VERSION ""

BS_:

BU_:

// TX20 / CAN ID 0x11A / 282
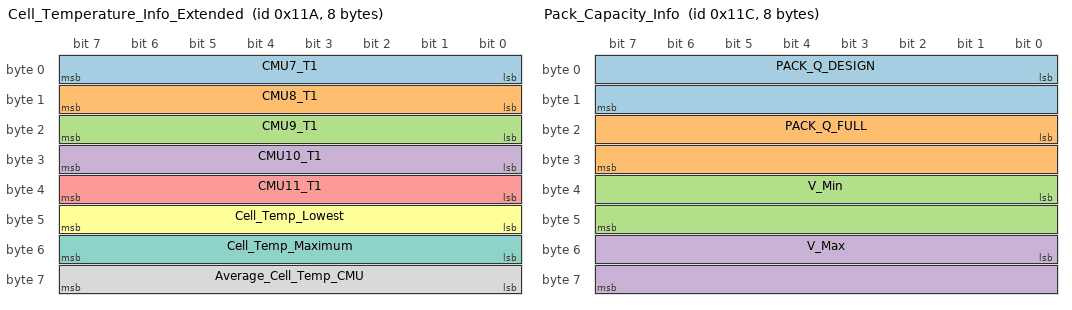
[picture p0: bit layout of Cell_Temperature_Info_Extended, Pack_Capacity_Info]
BO_ 282 Cell_Temperature_Info_Extended: 8 Vector__XXX
 SG_ CMU7_T1           : 0|8@1- (1,0) [-40|125] "C" Vector__XXX
 SG_ CMU8_T1           : 8|8@1- (1,0) [-40|125] "C" Vector__XXX
 SG_ CMU9_T1           : 16|8@1- (1,0) [-40|125] "C" Vector__XXX
 SG_ CMU10_T1          : 24|8@1- (1,0) [-40|125] "C" Vector__XXX
 SG_ CMU11_T1          : 32|8@1- (1,0) [-40|125] "C" Vector__XXX
 SG_ Cell_Temp_Lowest   : 40|8@1- (1,0) [-40|125] "C" Vector__XXX
 SG_ Cell_Temp_Maximum  : 48|8@1- (1,0) [-40|125] "C" Vector__XXX
 SG_ Average_Cell_Temp_CMU : 56|8@1- (1,0) [-40|125] "C" Vector__XXX

// TX14 / CAN ID 0x11C / 284
BO_ 284 Pack_Capacity_Info: 8 Vector__XXX
 SG_ PACK_Q_DESIGN : 0|16@1+ (0.1,0) [0|180] "Ah" Vector__XXX
 SG_ PACK_Q_FULL   : 16|16@1+ (0.1,0) [0|180] "Ah" Vector__XXX
 SG_ V_Min         : 32|16@1+ (0.1,0) [1|4] "mV" Vector__XXX
 SG_ V_Max         : 48|16@1+ (0.1,0) [1|4] "mV" Vector__XXX

// TX11 / CAN ID 0x12A / 298
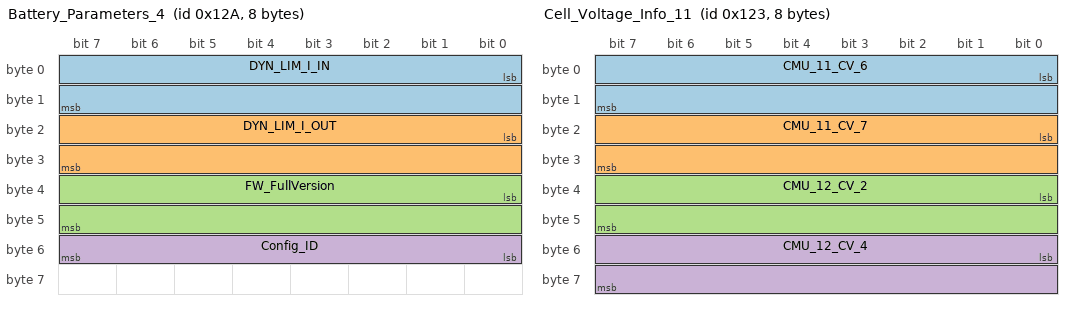
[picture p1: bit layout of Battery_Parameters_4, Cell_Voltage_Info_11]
BO_ 298 Battery_Parameters_4: 8 Vector__XXX
 SG_ DYN_LIM_I_IN : 0|16@1+ (0.1,0) [0|6553.5] "A" Vector__XXX
 SG_ DYN_LIM_I_OUT : 16|16@1+ (0.1,0) [0|6553.5] "A" Vector__XXX
 SG_ FW_FullVersion : 32|16@1+ (1,0) [0|65535] "" Vector__XXX
 SG_ Config_ID : 48|8@1+ (1,0) [0|255] "" Vector__XXX

// TX18 / CAN ID 0x123 / 291
BO_ 291 Cell_Voltage_Info_11: 8 Vector__XXX
 SG_ CMU_11_CV_6 : 0|16@1+ (0.1,0) [0|6553.5] "mV" Vector__XXX
 SG_ CMU_11_CV_7 : 16|16@1+ (0.1,0) [0|6553.5] "mV" Vector__XXX
 SG_ CMU_12_CV_2 : 32|16@1+ (0.1,0) [0|6553.5] "mV" Vector__XXX
 SG_ CMU_12_CV_4 : 48|16@1+ (0.1,0) [0|6553.5] "mV" Vector__XXX

// TX17 / CAN ID 0x122 / 290
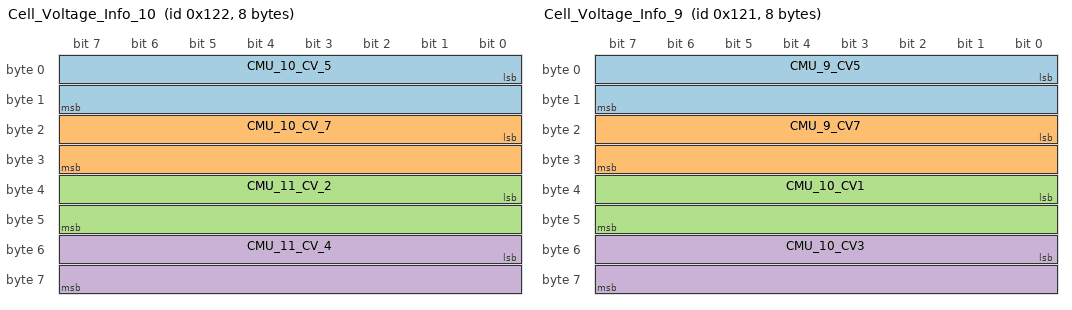
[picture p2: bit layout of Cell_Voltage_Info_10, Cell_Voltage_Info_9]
BO_ 290 Cell_Voltage_Info_10: 8 Vector__XXX
 SG_ CMU_10_CV_5 : 0|16@1+ (0.1,0) [0|6553.5] "mV" Vector__XXX
 SG_ CMU_10_CV_7 : 16|16@1+ (0.1,0) [0|6553.5] "mV" Vector__XXX
 SG_ CMU_11_CV_2 : 32|16@1+ (0.1,0) [0|6553.5] "mV" Vector__XXX
 SG_ CMU_11_CV_4 : 48|16@1+ (0.1,0) [0|6553.5] "mV" Vector__XXX

// TX16 / CAN ID 0x121 / 289
BO_ 289 Cell_Voltage_Info_9: 8 Vector__XXX
 SG_ CMU_9_CV5  : 0|16@1+ (0.1,0) [0|6553.5] "mV" Vector__XXX
 SG_ CMU_9_CV7  : 16|16@1+ (0.1,0) [0|6553.5] "mV" Vector__XXX
 SG_ CMU_10_CV1  : 32|16@1+ (0.1,0) [0|6553.5] "mV" Vector__XXX
 SG_ CMU_10_CV3  : 48|16@1+ (0.1,0) [0|6553.5] "mV" Vector__XXX

// TX15 / CAN ID 0x120 / 288
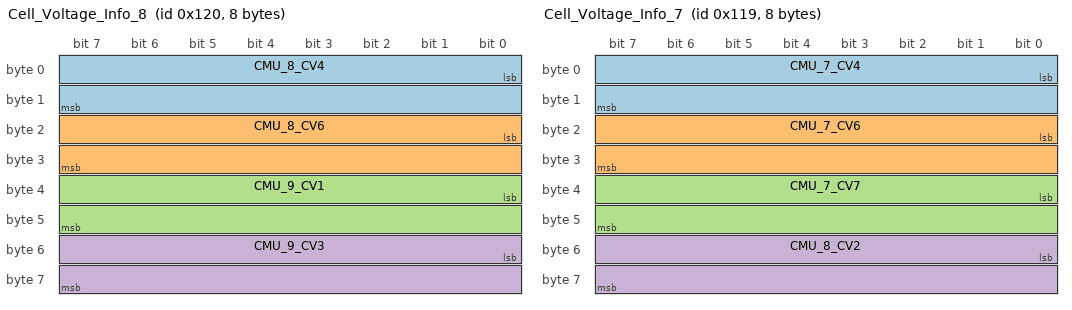
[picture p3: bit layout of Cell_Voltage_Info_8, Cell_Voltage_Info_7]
BO_ 288 Cell_Voltage_Info_8: 8 Vector__XXX
 SG_ CMU_8_CV4  : 0|16@1+ (0.1,0) [0|6553.5] "mV" Vector__XXX
 SG_ CMU_8_CV6 : 16|16@1+ (0.1,0) [0|6553.5] "mV" Vector__XXX
 SG_ CMU_9_CV1  : 32|16@1+ (0.1,0) [0|6553.5] "mV" Vector__XXX
 SG_ CMU_9_CV3  : 48|16@1+ (0.1,0) [0|6553.5] "mV" Vector__XXX

// TX13 / CAN ID 0x11A / 281
BO_ 281 Cell_Voltage_Info_7: 8 Vector__XXX
 SG_ CMU_7_CV4 : 0|16@1+ (0.1,0) [0|6553.5] "mV" Vector__XXX
 SG_ CMU_7_CV6 : 16|16@1+ (0.1,0) [0|6553.5] "mV" Vector__XXX
 SG_ CMU_7_CV7 : 32|16@1+ (0.1,0) [0|6553.5] "mV" Vector__XXX
 SG_ CMU_8_CV2 : 48|16@1+ (0.1,0) [0|6553.5] "mV" Vector__XXX

// TX9 / CAN ID 0x118 / 280
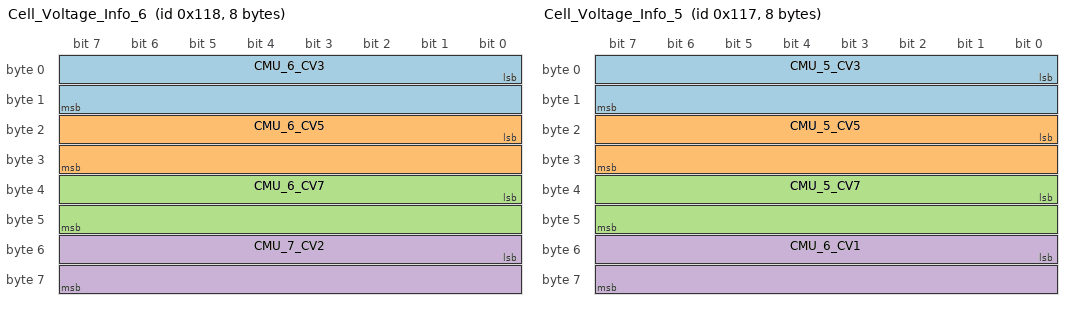
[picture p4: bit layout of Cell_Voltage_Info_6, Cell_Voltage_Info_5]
BO_ 280 Cell_Voltage_Info_6: 8 Vector__XXX
 SG_ CMU_6_CV3 : 0|16@1+ (0.1,0) [0|6553.5] "mV" Vector__XXX
 SG_ CMU_6_CV5 : 16|16@1+ (0.1,0) [0|6553.5] "mV" Vector__XXX
 SG_ CMU_6_CV7 : 32|16@1+ (0.1,0) [0|6553.5] "mV" Vector__XXX
 SG_ CMU_7_CV2 : 48|16@1+ (0.1,0) [0|6553.5] "mV" Vector__XXX

// TX8 / CAN ID 0x117 / 279
BO_ 279 Cell_Voltage_Info_5: 8 Vector__XXX
 SG_ CMU_5_CV3 : 0|16@1+ (0.1,0) [0|6553.5] "mV" Vector__XXX
 SG_ CMU_5_CV5 : 16|16@1+ (0.1,0) [0|6553.5] "mV" Vector__XXX
 SG_ CMU_5_CV7 : 32|16@1+ (0.1,0) [0|6553.5] "mV" Vector__XXX
 SG_ CMU_6_CV1 : 48|16@1+ (0.1,0) [0|6553.5] "mV" Vector__XXX

// TX7 / CAN ID 0x116 / 278
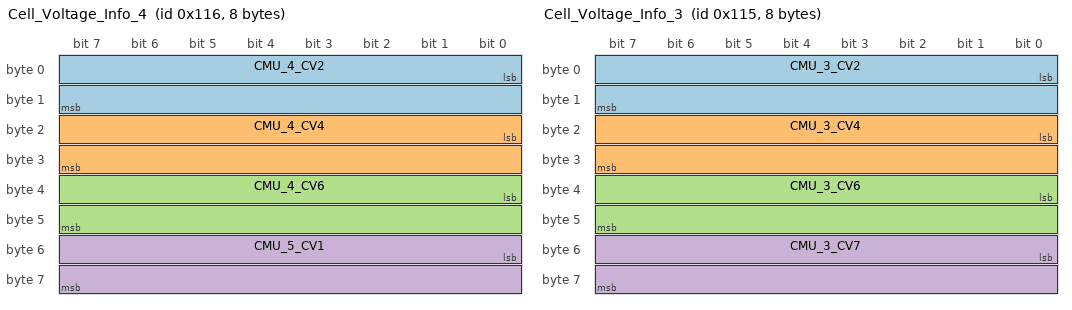
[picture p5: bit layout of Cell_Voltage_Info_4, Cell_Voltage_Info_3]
BO_ 278 Cell_Voltage_Info_4: 8 Vector__XXX
 SG_ CMU_4_CV2 : 0|16@1+ (0.1,0) [0|6553.5] "mV" Vector__XXX
 SG_ CMU_4_CV4 : 16|16@1+ (0.1,0) [0|6553.5] "mV" Vector__XXX
 SG_ CMU_4_CV6 : 32|16@1+ (0.1,0) [0|6553.5] "mV" Vector__XXX
 SG_ CMU_5_CV1 : 48|16@1+ (0.1,0) [0|6553.5] "mV" Vector__XXX

// TX6 / CAN ID 0x115 / 277
BO_ 277 Cell_Voltage_Info_3: 8 Vector__XXX
 SG_ CMU_3_CV2 : 0|16@1+ (0.1,0) [0|6553.5] "mV" Vector__XXX
 SG_ CMU_3_CV4 : 16|16@1+ (0.1,0) [0|6553.5] "mV" Vector__XXX
 SG_ CMU_3_CV6 : 32|16@1+ (0.1,0) [0|6553.5] "mV" Vector__XXX
 SG_ CMU_3_CV7 : 48|16@1+ (0.1,0) [0|6553.5] "mV" Vector__XXX

// TX5 / CAN ID 0x114 / 276
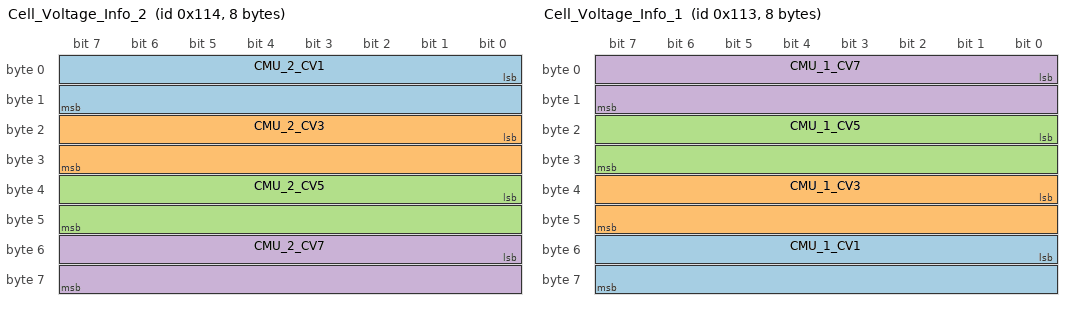
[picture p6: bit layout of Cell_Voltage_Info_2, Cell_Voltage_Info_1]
BO_ 276 Cell_Voltage_Info_2: 8 Vector__XXX
 SG_ CMU_2_CV1 : 0|16@1+ (0.1,0) [0|6553.5] "mV" Vector__XXX
 SG_ CMU_2_CV3 : 16|16@1+ (0.1,0) [0|6553.5] "mV" Vector__XXX
 SG_ CMU_2_CV5 : 32|16@1+ (0.1,0) [0|6553.5] "mV" Vector__XXX
 SG_ CMU_2_CV7 : 48|16@1+ (0.1,0) [0|6553.5] "mV" Vector__XXX

// TX4 / CAN ID 0x113 / 275
BO_ 275 Cell_Voltage_Info_1: 8 Vector__XXX
 SG_ CMU_1_CV1 : 48|16@1+ (0.1,0) [0|6553.5] "mV" Vector__XXX
 SG_ CMU_1_CV3 : 32|16@1+ (0.1,0) [0|6553.5] "mV" Vector__XXX
 SG_ CMU_1_CV5 : 16|16@1+ (0.1,0) [0|6553.5] "mV" Vector__XXX
 SG_ CMU_1_CV7 : 0|16@1+ (0.1,0) [0|6553.5] "mV" Vector__XXX

// TX3 / CAN ID 0x112 / 274
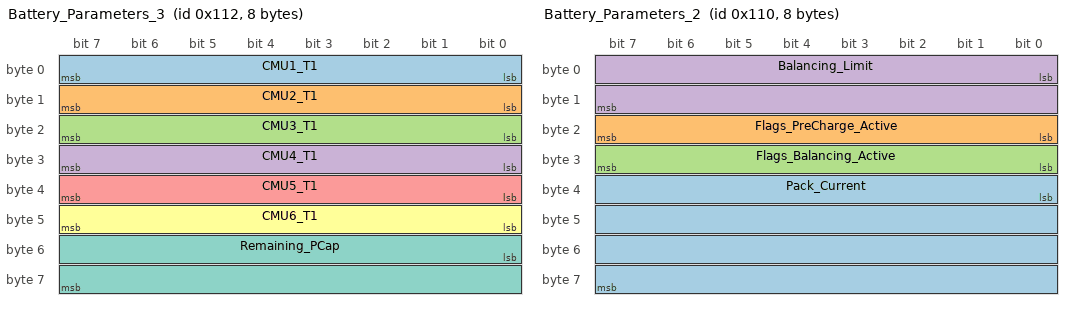
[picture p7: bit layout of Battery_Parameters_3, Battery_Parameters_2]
BO_ 274 Battery_Parameters_3: 8 Vector__XXX
 SG_ CMU1_T1 : 0|8@1- (1,0) [-40|125] "C" Vector__XXX
 SG_ CMU2_T1 : 8|8@1- (1,0) [-40|125] "C" Vector__XXX
 SG_ CMU3_T1 : 16|8@1- (1,0) [-40|125] "C" Vector__XXX
 SG_ CMU4_T1 : 24|8@1- (1,0) [-40|125] "C" Vector__XXX
 SG_ CMU5_T1 : 32|8@1- (1,0) [-40|125] "C" Vector__XXX
 SG_ CMU6_T1 : 40|8@1- (1,0) [-40|125] "C" Vector__XXX
 SG_ Remaining_PCap     : 48|16@1+ (0.1,0) [0|180] "Ah" Vector__XXX

// TX1 / CAN ID 0x110 / 272
BO_ 272 Battery_Parameters_2: 8 Vector__XXX
 SG_ Pack_Current : 32|32@1- (1e-005,0) [21474.8|21474.8] "A" Vector__XXX
 SG_ Flags_PreCharge_Active : 16|8@1+ (1,0) [0|255] "" Vector__XXX
 SG_ Flags_Balancing_Active : 24|8@1+ (1,0) [0|255] "" Vector__XXX
 SG_ Balancing_Limit : 0|16@1+ (0.1,0) [0|6553.5] "mV" Vector__XXX

// TX2 / CAN ID 0x109 / 265
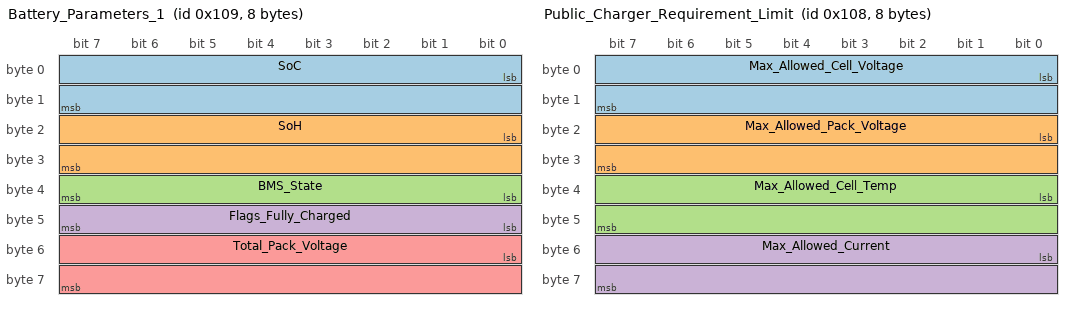
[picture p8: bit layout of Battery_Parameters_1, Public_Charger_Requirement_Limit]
BO_ 265 Battery_Parameters_1: 8 Vector__XXX
 SG_ SoC                  : 0|16@1+ (0.01,0) [0|655.35] "%" Vector__XXX
 SG_ SoH                  : 16|16@1+ (0.01,0) [0|655.35] "%" Vector__XXX
 SG_ BMS_State             : 32|8@1+ (1,0) [0|255] "" Vector__XXX
 SG_ Flags_Fully_Charged   : 40|8@1+ (1,0) [0|255] "" Vector__XXX
 SG_ Total_Pack_Voltage    : 48|16@1+ (0.1,0) [0|6553.5] "V" Vector__XXX
VAL_ 265 Flag_Fully_Charged  0 "False" 1 "True" ;
VAL_ 265 BMS_State           0 "INIT" 1 "Ready" 2 "Precharge" 3 "Active" 4 "Error" ;

// TX12 / CAN ID 0x108 / 264
BO_ 264 Public_Charger_Requirement_Limit: 8 Vector__XXX
 SG_ Max_Allowed_Cell_Voltage : 0|16@1+ (1,0) [0|65535] "mV" Vector__XXX
 SG_ Max_Allowed_Pack_Voltage : 16|16@1+ (1,0) [0|65535] "V" Vector__XXX
 SG_ Max_Allowed_Cell_Temp : 32|16@1+ (1,0) [0|65535] "C" Vector__XXX
 SG_ Max_Allowed_Current : 48|16@1+ (1,0) [0|65535] "A" Vector__XXX

// TX10 / CAN ID 0x107 / 263
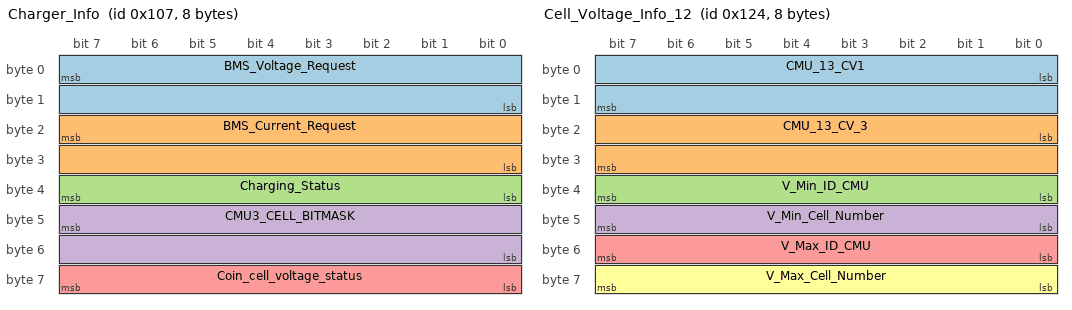
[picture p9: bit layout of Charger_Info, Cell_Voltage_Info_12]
BO_ 263 Charger_Info: 8 Vector__XXX
 SG_ BMS_Voltage_Request : 7|16@0+ (0.1,0) [0|6553.5] "V" Vector__XXX
 SG_ BMS_Current_Request : 23|16@0+ (0.1,0) [0|6553.5] "A" Vector__XXX
 SG_ Charging_Status : 39|8@0+ (1,0) [0|255] "" Vector__XXX
 SG_ CMU3_CELL_BITMASK : 47|16@0+ (1,0) [0|65535] "" Vector__XXX
 SG_ Coin_cell_voltage_status : 63|8@0+ (1,0) [0|255] "" Vector__XXX

// TX19 / CAN ID 0x124 / 292
BO_ 292 Cell_Voltage_Info_12: 8 Vector__XXX
 SG_ CMU_13_CV1   : 0|16@1+ (0.1,0) [0|6553.5] "mV" Vector__XXX
 SG_ CMU_13_CV_3  : 16|16@1+ (0.1,0) [0|6553.5] "mV" Vector__XXX
 SG_ V_Min_ID_CMU         : 32|8@1+ (1,0) [0|255] "" Vector__XXX
 SG_ V_Min_Cell_Number    : 40|8@1+ (1,0) [0|255] "" Vector__XXX
 SG_ V_Max_ID_CMU         : 48|8@1+ (1,0) [0|255] "" Vector__XXX
 SG_ V_Max_Cell_Number    : 56|8@1+ (1,0) [0|255] "" Vector__XXX

BO_ 600 Active_Error: 8 Vector__XXX
 SG_ Active_error_Count : 40|16@1+ (1,0) [0|65535] "" Vector__XXX

BO_ 602 Error_Code_1: 8 Vector__XXX
 SG_ Error_Code_1 : 55|16@0+ (1,0) [0|65535] "" Vector__XXX

BO_ 603 Error_Code_2: 8 Vector__XXX
 SG_ Error_Code_2 : 55|16@0+ (1,0) [0|65535] "" Vector__XXX

BO_ 604 Error_Code_3: 8 Vector__XXX
 SG_ Error_Code_3 : 55|16@0+ (1,0) [0|65535] "" Vector__XXX

BO_ 605 Error_Code_4: 8 Vector__XXX
 SG_ Error_Code_4 : 55|16@0+ (1,0) [0|65535] "" Vector__XXX

BO_ 606 Error_Code_5: 8 Vector__XXX
 SG_ Error_Code_5 : 55|16@0+ (1,0) [0|65535] "" Vector__XXX

BO_ 607 Error_Code_6: 8 Vector__XXX
 SG_ Error_Code_6 : 55|16@0+ (1,0) [0|65535] "" Vector__XXX

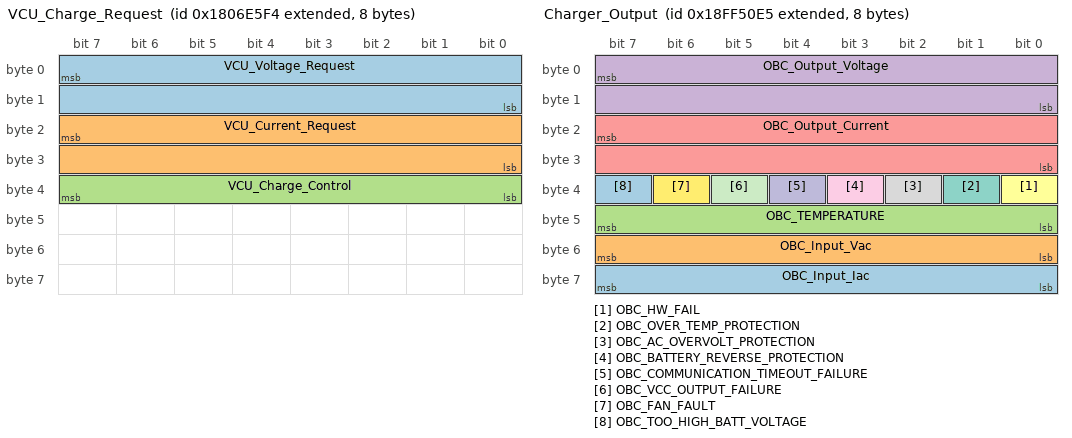
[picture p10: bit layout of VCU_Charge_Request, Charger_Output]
BO_ 2550588916 VCU_Charge_Request: 8 Vector__XXX
 SG_ VCU_Voltage_Request : 7|16@0+ (0.1,0) [0|6553.5] "V" Vector__XXX
 SG_ VCU_Current_Request : 23|16@0+ (0.1,0) [0|6553.5] "A" Vector__XXX
 SG_ VCU_Charge_Control  : 39|8@0+ (1,0) [0|1] "" Vector__XXX

BO_ 2566869221 Charger_Output: 8 Vector__XXX
 SG_ OBC_Input_Iac : 63|8@0+ (0.1,0) [0|25.5] "A" Vector__XXX
 SG_ OBC_Input_Vac : 55|8@0+ (2,0) [0|510] "V" Vector__XXX
 SG_ OBC_TEMPERATURE : 47|8@0+ (1,-100) [-100|155] "°C" Vector__XXX
 SG_ OBC_Output_Voltage : 7|16@0+ (0.1,0) [0|6553.5] "V" Vector__XXX
 SG_ OBC_Output_Current : 23|16@0+ (0.1,0) [0|6553.5] "A" Vector__XXX
 SG_ OBC_HW_FAIL : 32|1@0- (1,0) [0|1] "" Vector__XXX
 SG_ OBC_OVER_TEMP_PROTECTION : 33|1@0- (1,0) [0|1] "" Vector__XXX
 SG_ OBC_AC_OVERVOLT_PROTECTION : 34|1@0- (1,0) [0|1] "" Vector__XXX
 SG_ OBC_BATTERY_REVERSE_PROTECTION : 35|1@0- (1,0) [0|1] "" Vector__XXX
 SG_ OBC_COMMUNICATION_TIMEOUT_FAILURE : 36|1@0- (1,0) [0|1] "" Vector__XXX
 SG_ OBC_VCC_OUTPUT_FAILURE : 37|1@0- (1,0) [0|1] "" Vector__XXX
 SG_ OBC_FAN_FAULT : 38|1@0- (1,0) [0|1] "" Vector__XXX
 SG_ OBC_TOO_HIGH_BATT_VOLTAGE : 39|1@0- (1,0) [0|1] "" Vector__XXX

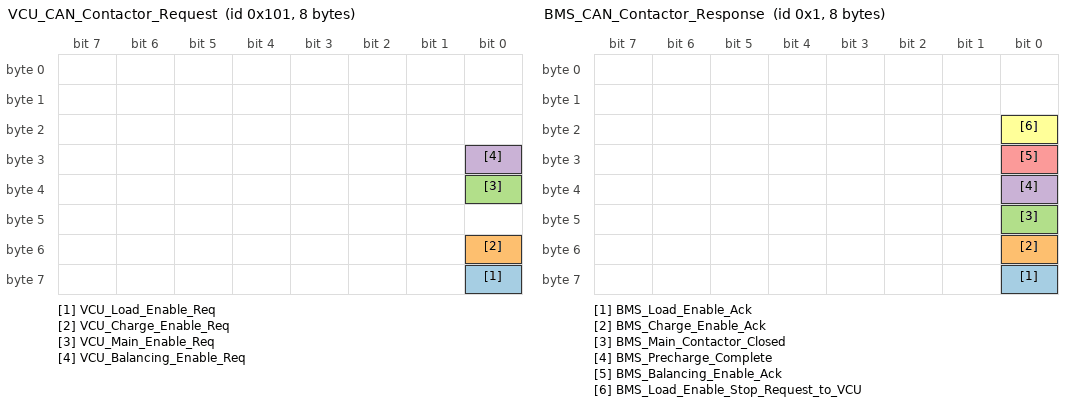
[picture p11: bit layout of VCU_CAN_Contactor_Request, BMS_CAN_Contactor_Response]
BO_ 257 VCU_CAN_Contactor_Request: 8 Vector__XXX
 SG_ VCU_Load_Enable_Req        : 56|1@1+ (1,0) [0|1] "" Vector__XXX
 SG_ VCU_Charge_Enable_Req      : 48|1@1+ (1,0) [0|1] "" Vector__XXX
 SG_ VCU_Main_Enable_Req        : 32|1@1+ (1,0) [0|1] "" Vector__XXX
 SG_ VCU_Balancing_Enable_Req   : 24|1@1+ (1,0) [0|1] "" Vector__XXX

BO_ 1 BMS_CAN_Contactor_Response: 8 Vector__XXX
 SG_ BMS_Load_Enable_Ack                 : 56|1@1+ (1,0) [0|1] "" Vector__XXX
 SG_ BMS_Charge_Enable_Ack               : 48|1@1+ (1,0) [0|1] "" Vector__XXX
 SG_ BMS_Main_Contactor_Closed           : 40|1@1+ (1,0) [0|1] "" Vector__XXX
 SG_ BMS_Precharge_Complete              : 32|1@1+ (1,0) [0|1] "" Vector__XXX
 SG_ BMS_Balancing_Enable_Ack            : 24|1@1+ (1,0) [0|1] "" Vector__XXX
 SG_ BMS_Load_Enable_Stop_Request_to_VCU : 16|1@1+ (1,0) [0|1] "" Vector__XXX

BO_ 1542 AuxVoltage: 8 Vector__XXX
 SG_ Aux_Voltage : 15|16@0+ (0.01,0) [0|655.35] "V" Vector__XXX

BO_ 1538 State: 8 Vector__XXX
 SG_ gunConnected : 48|8@1- (1,0) [0|0] "" Vector__XXX
 SG_ VehicleState : 56|8@1+ (1,0) [0|0] "" Vector__XXX
VAL_ 1538 VehicleState           0 "Off" 1 "Charge" 2 "Drive" 3 "Full Charge" 4 "Deep_Sleep" ;
